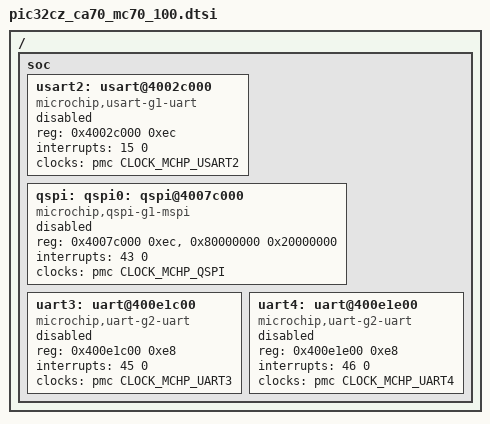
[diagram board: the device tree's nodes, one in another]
/*
 * SPDX-FileCopyrightText: Copyright (c) 2026 Microchip Technology Inc.
 *
 * SPDX-License-Identifier: Apache-2.0
 */

#include <microchip/pic32c/pic32cz_ca70_mc70/common/pic32cz_ca70_mc70.dtsi>

/ {
	soc {
		usart2: usart@4002c000 {
			compatible = "microchip,usart-g1-uart";
			reg = <0x4002c000 0xec>;
			interrupts = <15 0>;
			interrupt-names = "usart2";
			clocks = <&pmc CLOCK_MCHP_USART2>;
			clock-names = "mclk";
			status = "disabled";
		};

		qspi: qspi0: qspi@4007c000 {
			compatible = "microchip,qspi-g1-mspi";
			reg = <0x4007c000 0xec>, <0x80000000 0x20000000>;
			reg-names = "regs", "mmap";
			interrupts = <43 0>;
			interrupt-names = "qspi";
			clocks = <&pmc CLOCK_MCHP_QSPI>;
			clock-names = "mclk";
			#address-cells = <1>;
			#size-cells = <0>;
			status = "disabled";
		};

		uart3: uart@400e1c00 {
			compatible = "microchip,uart-g2-uart";
			reg = <0x400e1c00 0xe8>;
			interrupts = <45 0>;
			interrupt-names = "uart3";
			clocks = <&pmc CLOCK_MCHP_UART3>;
			clock-names = "mclk";
			status = "disabled";
		};

		uart4: uart@400e1e00 {
			compatible = "microchip,uart-g2-uart";
			reg = <0x400e1e00 0xe8>;
			interrupts = <46 0>;
			interrupt-names = "uart4";
			clocks = <&pmc CLOCK_MCHP_UART4>;
			clock-names = "mclk";
			status = "disabled";
		};
	};
};
